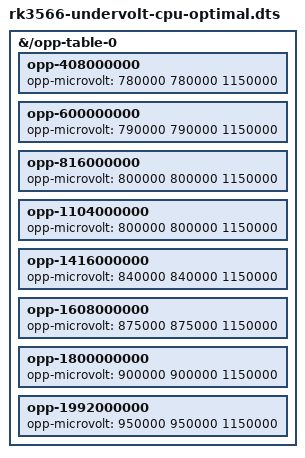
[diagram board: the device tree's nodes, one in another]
/*
 * RK3566 Optimized CPU Undervolt
 *
 * Voltage curve derived from 10M+ sample power profiling campaign
 * using external USB-PD power measurement (FNIRSI FNB58) correlated
 * with SCMI I2C PMIC telemetry. Statistical analysis (R, ANOVA,
 * Cohen's d effect sizes) across 12 profiling runs confirmed V²f
 * power model fit (R²=0.999).
 *
 * Conservative curve targeting the safe floor across binned silicon.
 * Validated stable on RGB30, RG353P, and X55 devices under sustained
 * emulation workloads (Dolphin, PPSSPP, N64).
 */
/dts-v1/;
/plugin/;

/ {
fragment@0 {
	target-path = "/opp-table-0";
	__overlay__ {
		opp-408000000  { opp-microvolt = <780000 780000 1150000>; };
		opp-600000000  { opp-microvolt = <790000 790000 1150000>; };
		opp-816000000  { opp-microvolt = <800000 800000 1150000>; };
		opp-1104000000 { opp-microvolt = <800000 800000 1150000>; };
		opp-1416000000 { opp-microvolt = <840000 840000 1150000>; };
		opp-1608000000 { opp-microvolt = <875000 875000 1150000>; };
		opp-1800000000 { opp-microvolt = <900000 900000 1150000>; };
		opp-1992000000 { opp-microvolt = <950000 950000 1150000>; };
	};
};
};
